# STM32H73x register map
File version: 1.3
CPU: CM7 r0p1, little endian, MPU, FPU, 4 interrupt priority bits
Registers are 32-bit, read-write, reset 0x0 unless marked. A register's access mark holds for its fields unless they carry their own. Offsets are from the block's base; [hi:lo] are bit positions.

## SCB_ACTRL — System control block ACTLR
Base 0xE000E008
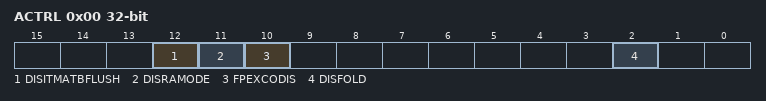
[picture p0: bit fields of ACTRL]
0x00 ACTRL — Auxiliary control register
  [12] DISITMATBFLUSH, [11] DISRAMODE, [10] FPEXCODIS, [2] DISFOLD

## SPDIFRX — Receiver Interface
Base 0x40004000
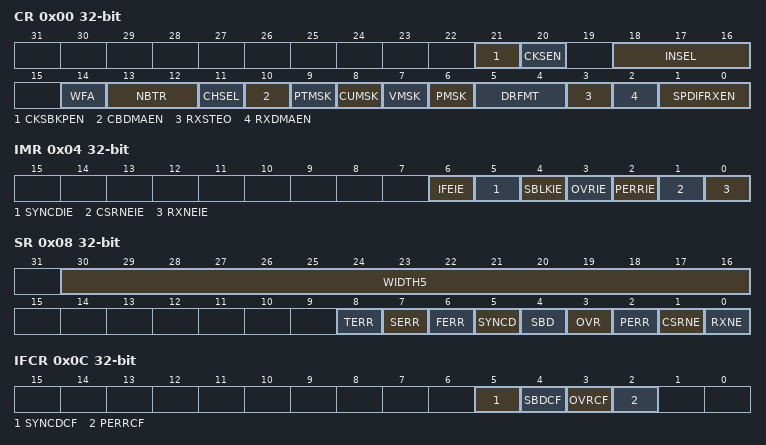
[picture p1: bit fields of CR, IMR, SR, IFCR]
0x00 CR — Control register
  [21] CKSBKPEN — Backup Symbol Clock Enable
  [20] CKSEN — Symbol Clock Enable
  [18:16] INSEL — input selection
  [14] WFA — Wait For Activity
  [13:12] NBTR — Maximum allowed re-tries during synchronization phase
  [11] CHSEL — Channel Selection
  [10] CBDMAEN — Control Buffer DMA ENable for control flow
  [9] PTMSK — Mask of Preamble Type bits
  [8] CUMSK — Mask of channel status and user bits
  [7] VMSK — Mask of Validity bit
  [6] PMSK — Mask Parity error bit
  [5:4] DRFMT — RX Data format
  [3] RXSTEO — STerEO Mode
  [2] RXDMAEN — Receiver DMA ENable for data flow
  [1:0] SPDIFRXEN — Peripheral Block Enable
0x04 IMR — Interrupt mask register
  [6] IFEIE — Serial Interface Error Interrupt Enable
  [5] SYNCDIE — Synchronization Done
  [4] SBLKIE — Synchronization Block Detected Interrupt Enable
  [3] OVRIE — Overrun error Interrupt Enable
  [2] PERRIE — Parity error interrupt enable
  [1] CSRNEIE — Control Buffer Ready Interrupt Enable
  [0] RXNEIE — RXNE interrupt enable
0x08 SR ro — Status register
  [30:16] WIDTH5 — Duration of 5 symbols counted with SPDIF_CLK
  [8] TERR — Time-out error
  [7] SERR — Synchronization error
  [6] FERR — Framing error
  [5] SYNCD — Synchronization Done
  [4] SBD — Synchronization Block Detected
  [3] OVR — Overrun error
  [2] PERR — Parity error
  [1] CSRNE — Control Buffer register is not empty
  [0] RXNE — Read data register not empty
0x0C IFCR wo — Interrupt Flag Clear register
  [5] SYNCDCF — Clears the Synchronization Done flag
  [4] SBDCF — Clears the Synchronization Block Detected flag
  [3] OVRCF — Clears the Overrun error flag
  [2] PERRCF — Clears the Parity error flag
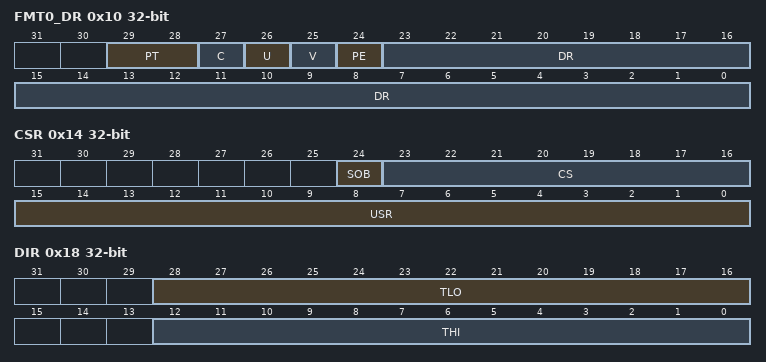
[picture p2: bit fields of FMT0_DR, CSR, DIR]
0x10 FMT0_DR ro — Data input register
  [29:28] PT — Preamble Type
  [27] C — Channel Status bit
  [26] U — User bit
  [25] V — Validity bit
  [24] PE — Parity Error bit
  [23:0] DR — Parity Error bit
0x14 CSR ro — Channel Status register
  [24] SOB — Start Of Block
  [23:16] CS — Channel A status information
  [15:0] USR — User data information
0x18 DIR ro — Debug Information register
  [28:16] TLO — Threshold LOW
  [12:0] THI — Threshold HIGH

## STK — SysTick timer
Base 0xE000E010
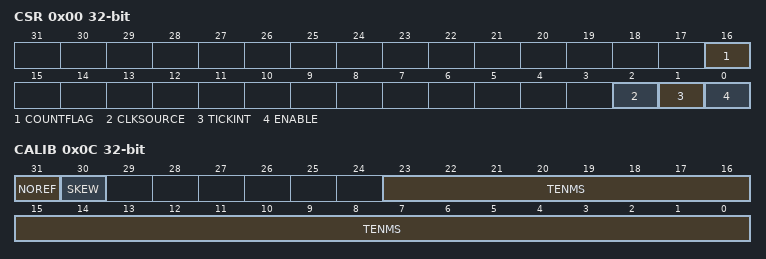
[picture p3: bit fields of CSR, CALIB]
0x00 CSR — SysTick control and status register
  [16] COUNTFLAG
  [2] CLKSOURCE — Clock source selection
  [1] TICKINT — SysTick exception request enable
  [0] ENABLE — Counter enable
0x04 RVR — SysTick reload value register
  [23:0] RELOAD — RELOAD value
0x08 CVR — SysTick current value register
  [23:0] CURRENT — Current counter value
0x0C CALIB — SysTick calibration value register
  [31] NOREF — NOREF flag. Reads as zero
  [30] SKEW — SKEW flag: Indicates whether the TENMS value is exact
  [23:0] TENMS — Calibration value

## SWPMI — Single Wire Protocol Master Interface
Base 0x40008800
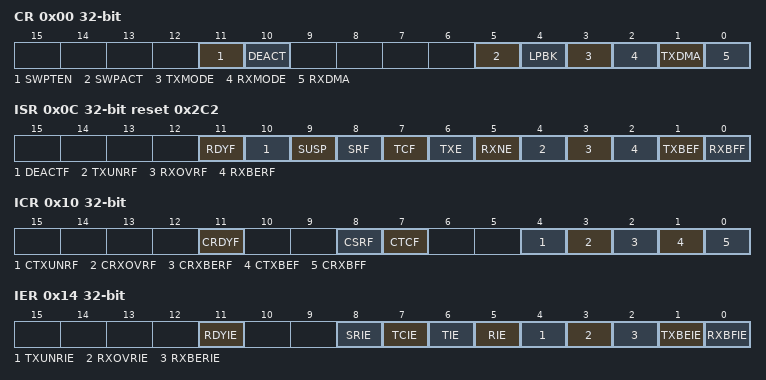
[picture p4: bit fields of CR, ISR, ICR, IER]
0x00 CR — SWPMI Configuration/Control register
  [11] SWPTEN — Single wire protocol master transceiver enable
  [10] DEACT — Single wire protocol master interface deactivate
  [5] SWPACT — Single wire protocol master interface activate
  [4] LPBK — Loopback mode enable
  [3] TXMODE — Transmission buffering mode
  [2] RXMODE — Reception buffering mode
  [1] TXDMA — Transmission DMA enable
  [0] RXDMA — Reception DMA enable
0x04 BRR reset 0x1 — SWPMI Bitrate register
  [7:0] BR — Bitrate prescaler
0x0C ISR ro reset 0x2C2 — SWPMI Interrupt and Status register
  [11] RDYF — transceiver ready flag
  [10] DEACTF — DEACTIVATED flag
  [9] SUSP — SUSPEND flag
  [8] SRF — Slave resume flag
  [7] TCF — Transfer complete flag
  [6] TXE — Transmit data register empty
  [5] RXNE — Receive data register not empty
  [4] TXUNRF — Transmit underrun error flag
  [3] RXOVRF — Receive overrun error flag
  [2] RXBERF — Receive CRC error flag
  [1] TXBEF — Transmit buffer empty flag
  [0] RXBFF — Receive buffer full flag
0x10 ICR wo — SWPMI Interrupt Flag Clear register
  [11] CRDYF — Clear transceiver ready flag
  [8] CSRF — Clear slave resume flag
  [7] CTCF — Clear transfer complete flag
  [4] CTXUNRF — Clear transmit underrun error flag
  [3] CRXOVRF — Clear receive overrun error flag
  [2] CRXBERF — Clear receive CRC error flag
  [1] CTXBEF — Clear transmit buffer empty flag
  [0] CRXBFF — Clear receive buffer full flag
0x14 IER — SWPMI Interrupt Enable register
  [11] RDYIE — Transceiver ready interrupt enable
  [8] SRIE — Slave resume interrupt enable
  [7] TCIE — Transmit complete interrupt enable
  [6] TIE — Transmit interrupt enable
  [5] RIE — Receive interrupt enable
  [4] TXUNRIE — Transmit underrun error interrupt enable
  [3] RXOVRIE — Receive overrun error interrupt enable
  [2] RXBERIE — Receive CRC error interrupt enable
  [1] TXBEIE — Transmit buffer empty interrupt enable
  [0] RXBFIE — Receive buffer full interrupt enable
0x18 RFL ro — SWPMI Receive Frame Length register
  [4:0] RFL — Receive frame length
0x1C TDR wo — SWPMI Transmit data register
  [31:0] TD — Transmit data
0x20 RDR ro — SWPMI Receive data register
  [31:0] RD — received data
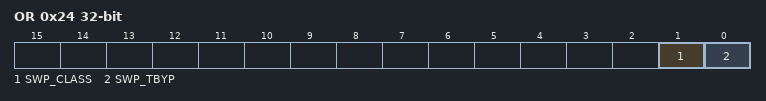
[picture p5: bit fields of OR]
0x24 OR — SWPMI Option register
  [1] SWP_CLASS — SWP class selection
  [0] SWP_TBYP — SWP transceiver bypass
